# CC2756 register map
File version: 1.0
CPU: CM4 r0p4, little endian, no MPU, no FPU, VTOR, 3 interrupt priority bits
Registers are 32-bit, read-write, reset 0x0 unless marked. A register's access mark holds for its fields unless they carry their own. Offsets are from the block's base; [hi:lo] are bit positions; {n}, {i} and the like mark numbered series; 'fields as' and 'values as' point back to an identical list.

## LRFDPBE32
Base 0x40081400
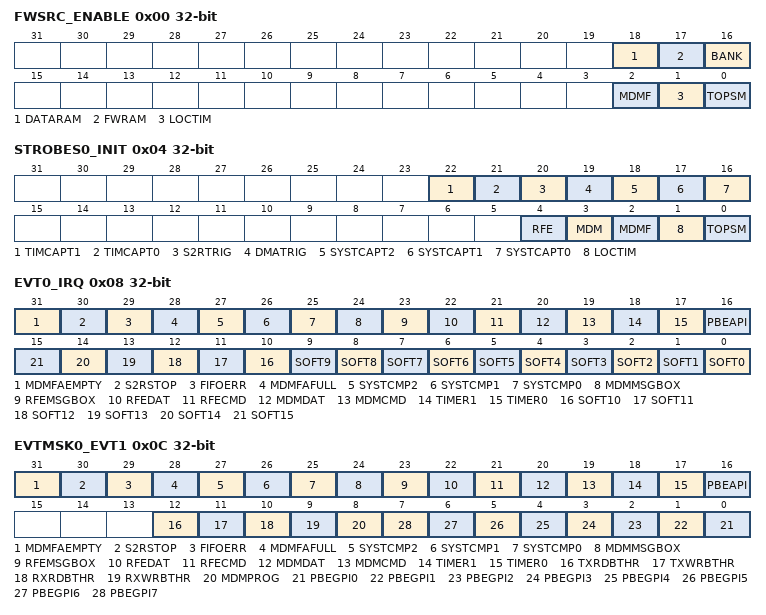
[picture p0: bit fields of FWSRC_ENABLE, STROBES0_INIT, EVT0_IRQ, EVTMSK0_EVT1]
0x00 FWSRC_ENABLE — Internal. Only to be used through TI provided API.
  [18] DATARAM — Internal. Only to be used through TI provided API.
    1=S2RRAM (Internal. Only to be used through TI provided API.); 0=PBERAM (Internal. Only to be used through TI provided API.)
  [17] FWRAM — Internal. Only to be used through TI provided API.
    values as DATARAM
  [16] BANK — Internal. Only to be used through TI provided API.
    1=ONE (Internal. Only to be used through TI provided API.); 0=ZERO (Internal. Only to be used through TI provided API.)
  [2] MDMF — Internal. Only to be used through TI provided API.
    1=EN (Internal. Only to be used through TI provided API.); 0=DIS (Internal. Only to be used through TI provided API.)
  [1] LOCTIM — Internal. Only to be used through TI provided API.
    values as MDMF
  [0] TOPSM — Internal. Only to be used through TI provided API.
    values as MDMF
0x04 STROBES0_INIT wo — Internal. Only to be used through TI provided API.
  [22] TIMCAPT1 — Internal. Only to be used through TI provided API.
    values as FWSRC_ENABLE.BANK
  [21] TIMCAPT0 — Internal. Only to be used through TI provided API.
    values as FWSRC_ENABLE.BANK
  [20] S2RTRIG — Internal. Only to be used through TI provided API.
    1=ARM (Internal. Only to be used through TI provided API.); 0=NO_EFFECT (Internal. Only to be used through TI provided API.)
  [19] DMATRIG — Internal. Only to be used through TI provided API.
    values as S2RTRIG
  [18] SYSTCAPT2 — Internal. Only to be used through TI provided API.
    values as FWSRC_ENABLE.BANK
  [17] SYSTCAPT1 — Internal. Only to be used through TI provided API.
    values as FWSRC_ENABLE.BANK
  [16] SYSTCAPT0 — Internal. Only to be used through TI provided API.
    values as FWSRC_ENABLE.BANK
  [4] RFE — Internal. Only to be used through TI provided API.
    1=RESET (Internal. Only to be used through TI provided API.); 0=NO_EFFECT (Internal. Only to be used through TI provided API.)
  [3] MDM — Internal. Only to be used through TI provided API.
    values as RFE
  [2] MDMF — Internal. Only to be used through TI provided API.
    values as RFE
  [1] LOCTIM — Internal. Only to be used through TI provided API.
    values as RFE
  [0] TOPSM — Internal. Only to be used through TI provided API.
    values as RFE
0x08 EVT0_IRQ wo — Internal. Only to be used through TI provided API.
  [31] MDMFAEMPTY ro — Internal. Only to be used through TI provided API.
    values as FWSRC_ENABLE.BANK
  [30] S2RSTOP ro — Internal. Only to be used through TI provided API.
    values as FWSRC_ENABLE.BANK
  [29] FIFOERR ro — Internal. Only to be used through TI provided API.
    values as FWSRC_ENABLE.BANK
  [28] MDMFAFULL ro — Internal. Only to be used through TI provided API.
    values as FWSRC_ENABLE.BANK
  [27] SYSTCMP2 ro — Internal. Only to be used through TI provided API.
    values as FWSRC_ENABLE.BANK
  [26] SYSTCMP1 ro — Internal. Only to be used through TI provided API.
    values as FWSRC_ENABLE.BANK
  [25] SYSTCMP0 ro — Internal. Only to be used through TI provided API.
    values as FWSRC_ENABLE.BANK
  [24] MDMMSGBOX ro — Internal. Only to be used through TI provided API.
    values as FWSRC_ENABLE.BANK
  [23] RFEMSGBOX ro — Internal. Only to be used through TI provided API.
    values as FWSRC_ENABLE.BANK
  [22] RFEDAT ro — Internal. Only to be used through TI provided API.
    values as FWSRC_ENABLE.BANK
  [21] RFECMD ro — Internal. Only to be used through TI provided API.
    values as FWSRC_ENABLE.BANK
  [20] MDMDAT ro — Internal. Only to be used through TI provided API.
    values as FWSRC_ENABLE.BANK
  [19] MDMCMD ro — Internal. Only to be used through TI provided API.
    values as FWSRC_ENABLE.BANK
  [18] TIMER1 ro — Internal. Only to be used through TI provided API.
    values as FWSRC_ENABLE.BANK
  [17] TIMER0 ro — Internal. Only to be used through TI provided API.
    values as FWSRC_ENABLE.BANK
  [16] PBEAPI ro — Internal. Only to be used through TI provided API.
    values as FWSRC_ENABLE.BANK
  [n] SOFT{n} (n=0..15) — Internal. Only to be used through TI provided API.
    1=ON (Internal. Only to be used through TI provided API.); 0=OFF (Internal. Only to be used through TI provided API.)
0x0C EVTMSK0_EVT1 ro — Internal. Only to be used through TI provided API.
  [31] MDMFAEMPTY — Internal. Only to be used through TI provided API.
    values as FWSRC_ENABLE.MDMF
  [30] S2RSTOP — Internal. Only to be used through TI provided API.
    values as FWSRC_ENABLE.MDMF
  [29] FIFOERR — Internal. Only to be used through TI provided API.
    values as FWSRC_ENABLE.MDMF
  [28] MDMFAFULL — Internal. Only to be used through TI provided API.
    values as FWSRC_ENABLE.MDMF
  [27] SYSTCMP2 — Internal. Only to be used through TI provided API.
    values as FWSRC_ENABLE.MDMF
  [26] SYSTCMP1 — Internal. Only to be used through TI provided API.
    values as FWSRC_ENABLE.MDMF
  [25] SYSTCMP0 — Internal. Only to be used through TI provided API.
    values as FWSRC_ENABLE.MDMF
  [24] MDMMSGBOX — Internal. Only to be used through TI provided API.
    values as FWSRC_ENABLE.MDMF
  [23] RFEMSGBOX — Internal. Only to be used through TI provided API.
    values as FWSRC_ENABLE.MDMF
  [22] RFEDAT — Internal. Only to be used through TI provided API.
    values as FWSRC_ENABLE.MDMF
  [21] RFECMD — Internal. Only to be used through TI provided API.
    values as FWSRC_ENABLE.MDMF
  [20] MDMDAT — Internal. Only to be used through TI provided API.
    values as FWSRC_ENABLE.MDMF
  [19] MDMCMD — Internal. Only to be used through TI provided API.
    values as FWSRC_ENABLE.MDMF
  [18] TIMER1 — Internal. Only to be used through TI provided API.
    values as FWSRC_ENABLE.MDMF
  [17] TIMER0 — Internal. Only to be used through TI provided API.
    values as FWSRC_ENABLE.MDMF
  [16] PBEAPI — Internal. Only to be used through TI provided API.
    values as FWSRC_ENABLE.MDMF
  [12] TXRDBTHR — Internal. Only to be used through TI provided API.
    1=MET (Internal. Only to be used through TI provided API.); 0=BELOW (Internal. Only to be used through TI provided API.)
  [11] TXWRBTHR — Internal. Only to be used through TI provided API.
    values as TXRDBTHR
  [10] RXRDBTHR — Internal. Only to be used through TI provided API.
    values as TXRDBTHR
  [9] RXWRBTHR — Internal. Only to be used through TI provided API.
    values as TXRDBTHR
  [8] MDMPROG — Internal. Only to be used through TI provided API.
    values as FWSRC_ENABLE.BANK
  [n] PBEGPI{n} (n=0..7) — Internal. Only to be used through TI provided API.
    values as FWSRC_ENABLE.BANK
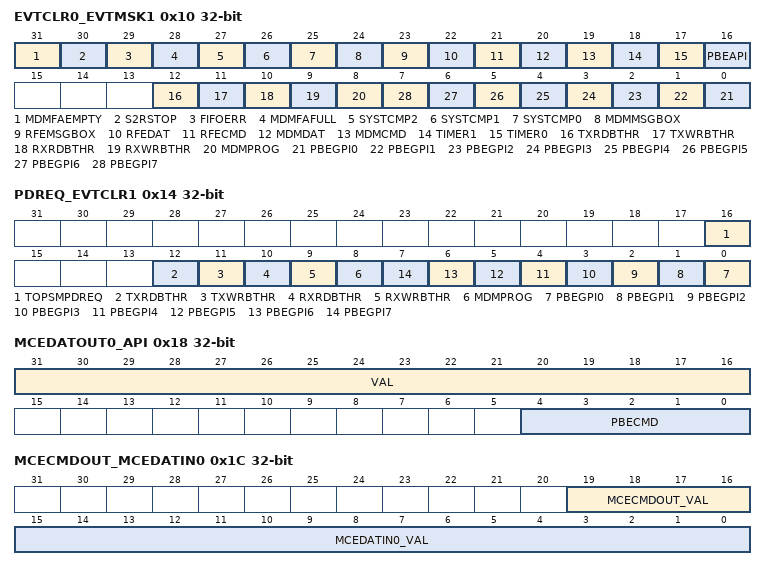
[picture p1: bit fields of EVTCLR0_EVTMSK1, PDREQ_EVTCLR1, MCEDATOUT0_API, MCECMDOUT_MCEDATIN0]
0x10 EVTCLR0_EVTMSK1 — Internal. Only to be used through TI provided API.
  [31] MDMFAEMPTY wo — Internal. Only to be used through TI provided API.
    1=CLEAR (Internal. Only to be used through TI provided API.); 0=RETAIN (Internal. Only to be used through TI provided API.)
  [30] S2RSTOP wo — Internal. Only to be used through TI provided API.
    values as MDMFAEMPTY
  [29] FIFOERR wo — Internal. Only to be used through TI provided API.
    values as MDMFAEMPTY
  [28] MDMFAFULL wo — Internal. Only to be used through TI provided API.
    values as MDMFAEMPTY
  [27] SYSTCMP2 wo — Internal. Only to be used through TI provided API.
    values as MDMFAEMPTY
  [26] SYSTCMP1 wo — Internal. Only to be used through TI provided API.
    values as MDMFAEMPTY
  [25] SYSTCMP0 wo — Internal. Only to be used through TI provided API.
    values as MDMFAEMPTY
  [24] MDMMSGBOX wo — Internal. Only to be used through TI provided API.
    values as MDMFAEMPTY
  [23] RFEMSGBOX wo — Internal. Only to be used through TI provided API.
    values as MDMFAEMPTY
  [22] RFEDAT wo — Internal. Only to be used through TI provided API.
    values as MDMFAEMPTY
  [21] RFECMD wo — Internal. Only to be used through TI provided API.
    values as MDMFAEMPTY
  [20] MDMDAT wo — Internal. Only to be used through TI provided API.
    values as MDMFAEMPTY
  [19] MDMCMD wo — Internal. Only to be used through TI provided API.
    values as MDMFAEMPTY
  [18] TIMER1 wo — Internal. Only to be used through TI provided API.
    values as MDMFAEMPTY
  [17] TIMER0 wo — Internal. Only to be used through TI provided API.
    values as MDMFAEMPTY
  [16] PBEAPI wo — Internal. Only to be used through TI provided API.
    values as MDMFAEMPTY
  [12] TXRDBTHR — Internal. Only to be used through TI provided API.
    values as FWSRC_ENABLE.MDMF
  [11] TXWRBTHR — Internal. Only to be used through TI provided API.
    values as FWSRC_ENABLE.MDMF
  [10] RXRDBTHR — Internal. Only to be used through TI provided API.
    values as FWSRC_ENABLE.MDMF
  [9] RXWRBTHR — Internal. Only to be used through TI provided API.
    values as FWSRC_ENABLE.MDMF
  [8] MDMPROG — Internal. Only to be used through TI provided API.
    values as FWSRC_ENABLE.MDMF
  [n] PBEGPI{n} (n=0..7) — Internal. Only to be used through TI provided API.
    values as FWSRC_ENABLE.MDMF
0x14 PDREQ_EVTCLR1 wo — Internal. Only to be used through TI provided API.
  [16] TOPSMPDREQ — Internal. Only to be used through TI provided API.
    values as EVT0_IRQ.SOFT0
  [12] TXRDBTHR — Internal. Only to be used through TI provided API.
    values as EVTCLR0_EVTMSK1.MDMFAEMPTY
  [11] TXWRBTHR — Internal. Only to be used through TI provided API.
    values as EVTCLR0_EVTMSK1.MDMFAEMPTY
  [10] RXRDBTHR — Internal. Only to be used through TI provided API.
    values as EVTCLR0_EVTMSK1.MDMFAEMPTY
  [9] RXWRBTHR — Internal. Only to be used through TI provided API.
    values as EVTCLR0_EVTMSK1.MDMFAEMPTY
  [8] MDMPROG — Internal. Only to be used through TI provided API.
    values as EVTCLR0_EVTMSK1.MDMFAEMPTY
  [n] PBEGPI{n} (n=0..7) — Internal. Only to be used through TI provided API.
    values as EVTCLR0_EVTMSK1.MDMFAEMPTY
0x18 MCEDATOUT0_API — Internal. Only to be used through TI provided API.
  [31:16] VAL — Internal. Only to be used through TI provided API.
    0xFFFF=ALLONES (Internal. Only to be used through TI provided API.); 0=ALLZEROS (Internal. Only to be used through TI provided API.)
  [4:0] PBECMD — Internal. Only to be used through TI provided API.
    31=ALLONES (Internal. Only to be used through TI provided API.); 0=ALLZEROS (Internal. Only to be used through TI provided API.)
0x1C MCECMDOUT_MCEDATIN0 ro — Internal. Only to be used through TI provided API.
  [19:16] MCECMDOUT_VAL — Internal. Only to be used through TI provided API.
    15=ALLONES (Internal. Only to be used through TI provided API.); 0=ALLZEROS (Internal. Only to be used through TI provided API.)
  [15:0] MCEDATIN0_VAL — Internal. Only to be used through TI provided API.
    values as MCEDATOUT0_API.VAL
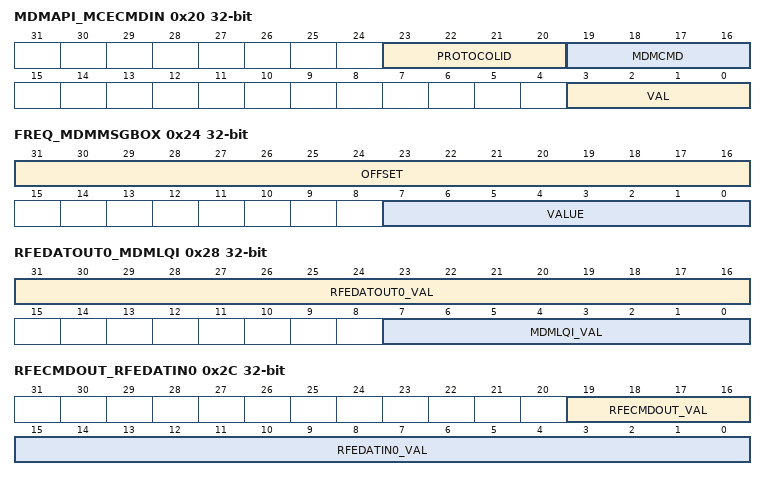
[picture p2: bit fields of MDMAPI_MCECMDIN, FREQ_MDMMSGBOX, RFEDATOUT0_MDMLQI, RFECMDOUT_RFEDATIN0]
0x20 MDMAPI_MCECMDIN ro — Internal. Only to be used through TI provided API.
  [all] fields
    values as MCECMDOUT_MCEDATIN0.MCECMDOUT_VAL
  [23:20] PROTOCOLID — Internal. Only to be used through TI provided API.
  [19:16] MDMCMD — Internal. Only to be used through TI provided API.
  [3:0] VAL — Internal. Only to be used through TI provided API.
0x24 FREQ_MDMMSGBOX ro — Internal. Only to be used through TI provided API.
  [31:16] OFFSET — Internal. Only to be used through TI provided API.
    values as MCEDATOUT0_API.VAL
  [7:0] VALUE — Internal. Only to be used through TI provided API.
    255=ALLONES (Internal. Only to be used through TI provided API.); 0=ALLZEROS (Internal. Only to be used through TI provided API.)
0x28 RFEDATOUT0_MDMLQI ro — Internal. Only to be used through TI provided API.
  [31:16] RFEDATOUT0_VAL — Internal. Only to be used through TI provided API.
    values as MCEDATOUT0_API.VAL
  [7:0] MDMLQI_VAL — Internal. Only to be used through TI provided API.
    values as FREQ_MDMMSGBOX.VALUE
0x2C RFECMDOUT_RFEDATIN0 ro — Internal. Only to be used through TI provided API.
  [19:16] RFECMDOUT_VAL — Internal. Only to be used through TI provided API.
    values as MCECMDOUT_MCEDATIN0.MCECMDOUT_VAL
  [15:0] RFEDATIN0_VAL — Internal. Only to be used through TI provided API.
    values as MCEDATOUT0_API.VAL
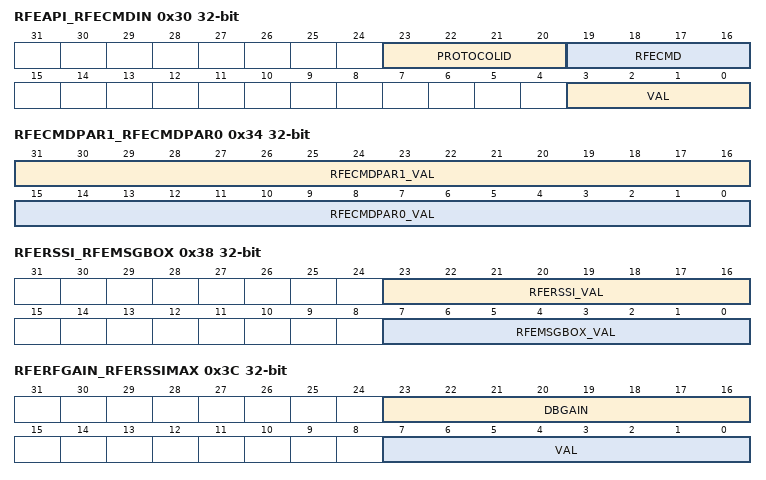
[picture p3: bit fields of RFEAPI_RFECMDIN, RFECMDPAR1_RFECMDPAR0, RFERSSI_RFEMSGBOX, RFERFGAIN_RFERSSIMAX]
0x30 RFEAPI_RFECMDIN ro — Internal. Only to be used through TI provided API.
  [all] fields
    values as MCECMDOUT_MCEDATIN0.MCECMDOUT_VAL
  [23:20] PROTOCOLID — Internal. Only to be used through TI provided API.
  [19:16] RFECMD — Internal. Only to be used through TI provided API.
  [3:0] VAL — Internal. Only to be used through TI provided API.
0x34 RFECMDPAR1_RFECMDPAR0 — Internal. Only to be used through TI provided API.
  [31:16] RFECMDPAR1_VAL — Internal. Only to be used through TI provided API.
    values as MCEDATOUT0_API.VAL
  [15:0] RFECMDPAR0_VAL — Internal. Only to be used through TI provided API.
    values as MCEDATOUT0_API.VAL
0x38 RFERSSI_RFEMSGBOX ro — Internal. Only to be used through TI provided API.
  [23:16] RFERSSI_VAL — Internal. Only to be used through TI provided API.
    values as FREQ_MDMMSGBOX.VALUE
  [7:0] RFEMSGBOX_VAL — Internal. Only to be used through TI provided API.
    values as FREQ_MDMMSGBOX.VALUE
0x3C RFERFGAIN_RFERSSIMAX ro — Internal. Only to be used through TI provided API.
  [23:16] DBGAIN — Internal. Only to be used through TI provided API.
    values as FREQ_MDMMSGBOX.VALUE
  [7:0] VAL — Internal. Only to be used through TI provided API.
    values as FREQ_MDMMSGBOX.VALUE
0x40 MDMSYNCA — Internal. Only to be used through TI provided API.
  [31:0] SWA
    values as MCEDATOUT0_API.VAL
0x44 MDMSYNCB — Internal. Only to be used through TI provided API.
  [31:0] SWB
    values as MCEDATOUT0_API.VAL
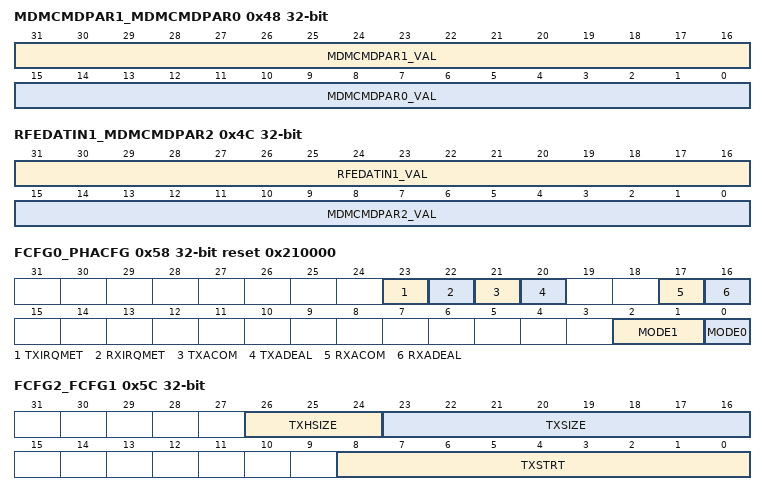
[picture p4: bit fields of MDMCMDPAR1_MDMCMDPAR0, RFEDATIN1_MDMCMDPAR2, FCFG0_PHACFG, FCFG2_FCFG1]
0x48 MDMCMDPAR1_MDMCMDPAR0 — Internal. Only to be used through TI provided API.
  [31:16] MDMCMDPAR1_VAL — Internal. Only to be used through TI provided API.
    values as MCEDATOUT0_API.VAL
  [15:0] MDMCMDPAR0_VAL — Internal. Only to be used through TI provided API.
    values as MCEDATOUT0_API.VAL
0x4C RFEDATIN1_MDMCMDPAR2 — Internal. Only to be used through TI provided API.
  [31:16] RFEDATIN1_VAL ro — Internal. Only to be used through TI provided API.
    values as MCEDATOUT0_API.VAL
  [15:0] MDMCMDPAR2_VAL — Internal. Only to be used through TI provided API.
    values as MCEDATOUT0_API.VAL
0x50 POLY0 — Internal. Only to be used through TI provided API.
  [31:0] VAL
    values as MCEDATOUT0_API.VAL
0x54 POLY1 — Internal. Only to be used through TI provided API.
  fields as POLY0
0x58 FCFG0_PHACFG reset 0x210000 — Internal. Only to be used through TI provided API.
  [23] TXIRQMET — Internal. Only to be used through TI provided API.
    1=TXRDBTHR (Internal. Only to be used through TI provided API.); 0=TXWRBTHR (Internal. Only to be used through TI provided API.)
  [22] RXIRQMET — Internal. Only to be used through TI provided API.
    1=RXWRBTHR (Internal. Only to be used through TI provided API.); 0=RXRDBTHR (Internal. Only to be used through TI provided API.)
  [21] TXACOM — Internal. Only to be used through TI provided API.
    values as FWSRC_ENABLE.MDMF
  [20] TXADEAL — Internal. Only to be used through TI provided API.
    values as FWSRC_ENABLE.MDMF
  [17] RXACOM — Internal. Only to be used through TI provided API.
    values as FWSRC_ENABLE.MDMF
  [16] RXADEAL — Internal. Only to be used through TI provided API.
    values as FWSRC_ENABLE.MDMF
  [2:1] MODE1 — Internal. Only to be used through TI provided API.
    2=PARAL (Internal. Only to be used through TI provided API.); 1=CASC (Internal. Only to be used through TI provided API.); 0=INDEP (Internal. Only to be used through TI provided API.)
  [0] MODE0 — Internal. Only to be used through TI provided API.
    1=WHITE (Internal. Only to be used through TI provided API.); 0=CRC (Internal. Only to be used through TI provided API.)
0x5C FCFG2_FCFG1 — Internal. Only to be used through TI provided API.
  [26:24] TXHSIZE — Internal. Only to be used through TI provided API.
    2=WORD (Internal. Only to be used through TI provided API.); 1=HALFW (Internal. Only to be used through TI provided API.); 0=BYTE (Internal. Only to be used through TI provided API.)
  [23:16] TXSIZE — Internal. Only to be used through TI provided API.
    255=ONES (Internal. Only to be used through TI provided API.); 0=ZEROS (Internal. Only to be used through TI provided API.)
  [8:0] TXSTRT — Internal. Only to be used through TI provided API.
    0x1FF=ONES (Internal. Only to be used through TI provided API.); 0=ZEROS (Internal. Only to be used through TI provided API.)
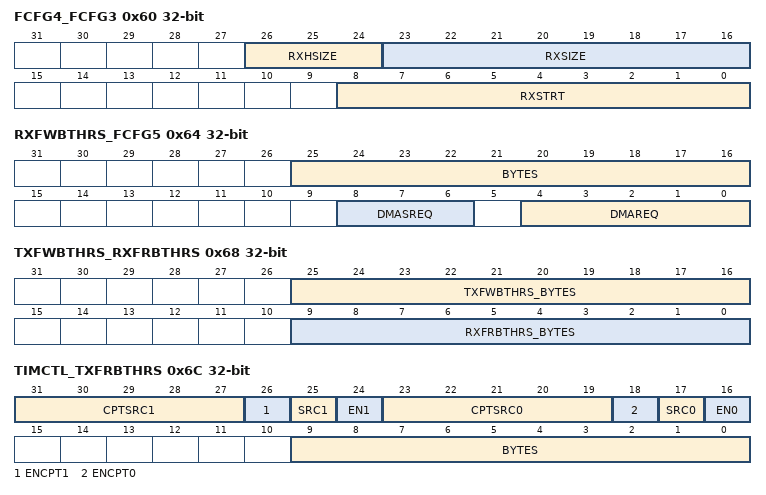
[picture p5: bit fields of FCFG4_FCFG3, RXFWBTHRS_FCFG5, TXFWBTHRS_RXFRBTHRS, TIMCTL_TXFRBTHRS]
0x60 FCFG4_FCFG3 — Internal. Only to be used through TI provided API.
  [26:24] RXHSIZE — Internal. Only to be used through TI provided API.
    values as FCFG2_FCFG1.TXHSIZE
  [23:16] RXSIZE — Internal. Only to be used through TI provided API.
    values as FCFG2_FCFG1.TXSIZE
  [8:0] RXSTRT — Internal. Only to be used through TI provided API.
    values as FCFG2_FCFG1.TXSTRT
0x64 RXFWBTHRS_FCFG5 — Internal. Only to be used through TI provided API.
  [25:16] BYTES — Internal. Only to be used through TI provided API.
    0x3FF=ALLONES (Internal. Only to be used through TI provided API.); 0=ALLZEROS (Internal. Only to be used through TI provided API.)
  [8:6] DMASREQ — Internal. Only to be used through TI provided API.
    4=TXFIFOFREE (Internal. Only to be used through TI provided API.); 3=TXFIFOMD (Internal. Only to be used through TI provided API.); 2=RXFIFOFREE (Internal. Only to be used through TI provided API.); 1=RXFIFOMD (Internal. Only to be used through TI provided API.); 0=NONE (Internal. Only to be used through TI provided API.)
  [4:0] DMAREQ — Internal. Only to be used through TI provided API.
    15=TXFIFO_COMMIT (Internal. Only to be used through TI provided API.); 14=TXFIFO_DISCARD (Internal. Only to be used through TI provided API.); 13=TXFIFO_RETRY (Internal. Only to be used through TI provided API.); 12=TXFIFO_DEALLOC (Internal. Only to be used through TI provided API.); 11=TXFIFO_RESET (Internal. Only to be used through TI provided API.); 10=TXWRBTHR_MET (Internal. Only to be used through TI provided API.); 9=TXRDBTHR_MET (Internal. Only to be used through TI provided API.); 7=RXFIFO_COMMIT (Internal. Only to be used through TI provided API.); 6=RXFIFO_DISCARD (Internal. Only to be used through TI provided API.); 5=RXFIFO_RETRY (Internal. Only to be used through TI provided API.); 4=RXFIFO_DEALLOC (Internal. Only to be used through TI provided API.); 3=RXFIFO_RESET (Internal. Only to be used through TI provided API.); 2=RXWRBTHR_MET (Internal. Only to be used through TI provided API.); 1=RXRDBTHR_MET (Internal. Only to be used through TI provided API.); 0=NONE (Internal. Only to be used through TI provided API.)
0x68 TXFWBTHRS_RXFRBTHRS — Internal. Only to be used through TI provided API.
  [25:16] TXFWBTHRS_BYTES — Internal. Only to be used through TI provided API.
    values as RXFWBTHRS_FCFG5.BYTES
  [9:0] RXFRBTHRS_BYTES — Internal. Only to be used through TI provided API.
    values as RXFWBTHRS_FCFG5.BYTES
0x6C TIMCTL_TXFRBTHRS — Internal. Only to be used through TI provided API.
  [31:27] CPTSRC1 — Internal. Only to be used through TI provided API.
    values as MCEDATOUT0_API.PBECMD
  [26] ENCPT1 — Internal. Only to be used through TI provided API.
    values as EVT0_IRQ.SOFT0
  [25] SRC1 — Internal. Only to be used through TI provided API.
    1=PRE1 (Internal. Only to be used through TI provided API.); 0=CLK (Internal. Only to be used through TI provided API.)
  [24] EN1 — Internal. Only to be used through TI provided API.
    values as EVT0_IRQ.SOFT0
  [23:19] CPTSRC0 — Internal. Only to be used through TI provided API.
    values as MCEDATOUT0_API.PBECMD
  [18] ENCPT0 — Internal. Only to be used through TI provided API.
    values as EVT0_IRQ.SOFT0
  [17] SRC0 — Internal. Only to be used through TI provided API.
    1=PRE0 (Internal. Only to be used through TI provided API.); 0=CLK (Internal. Only to be used through TI provided API.)
  [16] EN0 — Internal. Only to be used through TI provided API.
    values as EVT0_IRQ.SOFT0
  [9:0] BYTES — Internal. Only to be used through TI provided API.
    values as RXFWBTHRS_FCFG5.BYTES
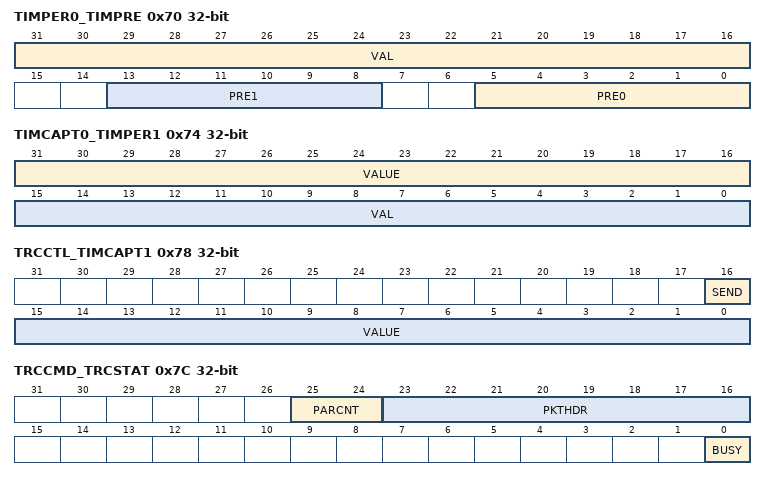
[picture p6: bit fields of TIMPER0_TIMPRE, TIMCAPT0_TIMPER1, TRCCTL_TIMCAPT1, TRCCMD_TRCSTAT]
0x70 TIMPER0_TIMPRE — Internal. Only to be used through TI provided API.
  [31:16] VAL — Internal. Only to be used through TI provided API.
    values as MCEDATOUT0_API.VAL
  [13:8] PRE1 — Internal. Only to be used through TI provided API.
    63=DIV64 (Internal. Only to be used through TI provided API.); 0=NO_DIV (Internal. Only to be used through TI provided API.)
  [5:0] PRE0 — Internal. Only to be used through TI provided API.
    values as PRE1
0x74 TIMCAPT0_TIMPER1 — Internal. Only to be used through TI provided API.
  [31:16] VALUE ro — Internal. Only to be used through TI provided API.
    values as MCEDATOUT0_API.VAL
  [15:0] VAL — Internal. Only to be used through TI provided API.
    values as MCEDATOUT0_API.VAL
0x78 TRCCTL_TIMCAPT1 ro — Internal. Only to be used through TI provided API.
  [16] SEND wo — Internal. Only to be used through TI provided API.
    values as FWSRC_ENABLE.BANK
  [15:0] VALUE — Internal. Only to be used through TI provided API.
    values as MCEDATOUT0_API.VAL
0x7C TRCCMD_TRCSTAT ro — Internal. Only to be used through TI provided API.
  [25:24] PARCNT — Internal. Only to be used through TI provided API.
    3=ALLONES (Internal. Only to be used through TI provided API.); 0=ALLZEROS (Internal. Only to be used through TI provided API.)
  [23:16] PKTHDR — Internal. Only to be used through TI provided API.
    values as FREQ_MDMMSGBOX.VALUE
  [0] BUSY — Internal. Only to be used through TI provided API.
    values as FWSRC_ENABLE.BANK
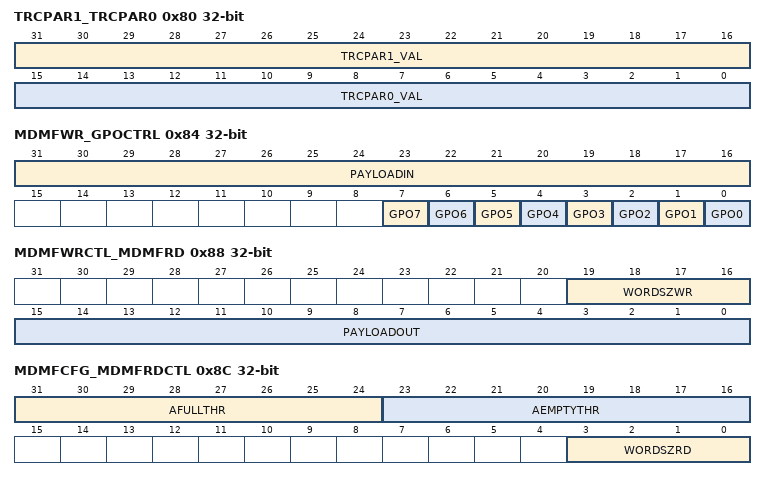
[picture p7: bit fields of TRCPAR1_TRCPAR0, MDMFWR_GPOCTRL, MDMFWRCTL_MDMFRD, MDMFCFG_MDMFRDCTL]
0x80 TRCPAR1_TRCPAR0 — Internal. Only to be used through TI provided API.
  [31:16] TRCPAR1_VAL — Internal. Only to be used through TI provided API.
    values as MCEDATOUT0_API.VAL
  [15:0] TRCPAR0_VAL — Internal. Only to be used through TI provided API.
    values as MCEDATOUT0_API.VAL
0x84 MDMFWR_GPOCTRL — Internal. Only to be used through TI provided API.
  [31:16] PAYLOADIN — Internal. Only to be used through TI provided API.
    values as MCEDATOUT0_API.VAL
  [n] GPO{n} (n=0..7) — Internal. Only to be used through TI provided API.
    values as FWSRC_ENABLE.BANK
0x88 MDMFWRCTL_MDMFRD ro — Internal. Only to be used through TI provided API.
  [19:16] WORDSZWR — Internal. Only to be used through TI provided API.
    {v}=BITS{v+1} (Internal. Only to be used through TI provided API.) (v=0..15)
  [15:0] PAYLOADOUT — Internal. Only to be used through TI provided API.
    values as MCEDATOUT0_API.VAL
0x8C MDMFCFG_MDMFRDCTL — Internal. Only to be used through TI provided API.
  [31:24] AFULLTHR — Internal. Only to be used through TI provided API.
    values as FREQ_MDMMSGBOX.VALUE
  [23:16] AEMPTYTHR — Internal. Only to be used through TI provided API.
    values as FREQ_MDMMSGBOX.VALUE
  [3:0] WORDSZRD — Internal. Only to be used through TI provided API.
    values as MDMFWRCTL_MDMFRD.WORDSZWR
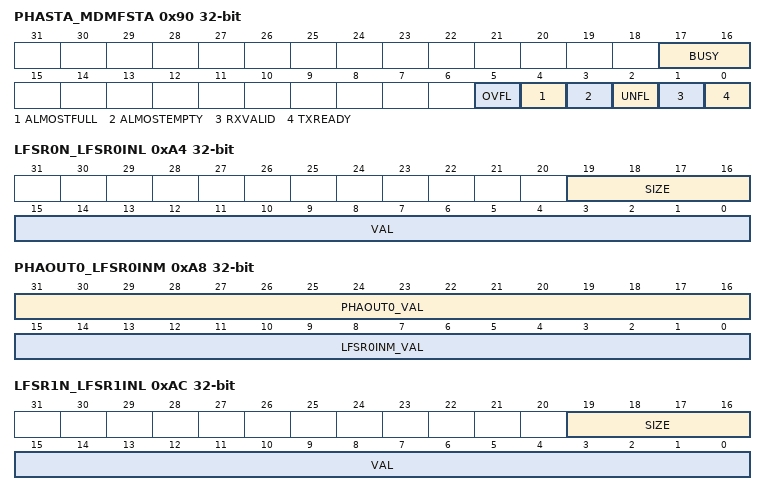
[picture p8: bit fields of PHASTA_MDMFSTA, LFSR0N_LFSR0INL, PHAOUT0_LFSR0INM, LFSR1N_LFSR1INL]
0x90 PHASTA_MDMFSTA ro — Internal. Only to be used through TI provided API.
  [17:16] BUSY — Internal. Only to be used through TI provided API.
    1=BUSY (Internal. Only to be used through TI provided API.); 0=IDLE (Internal. Only to be used through TI provided API.)
  [5] OVFL — Internal. Only to be used through TI provided API.
    values as FWSRC_ENABLE.BANK
  [4] ALMOSTFULL — Internal. Only to be used through TI provided API.
    values as FWSRC_ENABLE.BANK
  [3] ALMOSTEMPTY — Internal. Only to be used through TI provided API.
    values as FWSRC_ENABLE.BANK
  [2] UNFL — Internal. Only to be used through TI provided API.
    values as FWSRC_ENABLE.BANK
  [1] RXVALID — Internal. Only to be used through TI provided API.
    values as FWSRC_ENABLE.BANK
  [0] TXREADY — Internal. Only to be used through TI provided API.
    values as FWSRC_ENABLE.BANK
0x94 LFSR0 reset 0xFFFFFFFF — Internal. Only to be used through TI provided API.
  fields as POLY0
0x98 LFSR0BR reset 0xFFFFFFFF — Internal. Only to be used through TI provided API.
  fields as POLY0
0x9C LFSR1 reset 0xFFFFFFFF — Internal. Only to be used through TI provided API.
  fields as POLY0
0xA0 LFSR1BR reset 0xFFFFFFFF — Internal. Only to be used through TI provided API.
  fields as POLY0
0xA4 LFSR0N_LFSR0INL wo — Internal. Only to be used through TI provided API.
  [19:16] SIZE — Internal. Only to be used through TI provided API.
    values as MCECMDOUT_MCEDATIN0.MCECMDOUT_VAL
  [15:0] VAL — Internal. Only to be used through TI provided API.
    values as TRCCMD_TRCSTAT.PARCNT
0xA8 PHAOUT0_LFSR0INM wo — Internal. Only to be used through TI provided API.
  [31:16] PHAOUT0_VAL — Internal. Only to be used through TI provided API.
    0xDCD7=ALLONES (Internal. Only to be used through TI provided API.); 0=ALLZEROS (Internal. Only to be used through TI provided API.)
  [15:0] LFSR0INM_VAL — Internal. Only to be used through TI provided API.
    values as FWSRC_ENABLE.BANK
0xAC LFSR1N_LFSR1INL wo — Internal. Only to be used through TI provided API.
  fields as LFSR0N_LFSR0INL
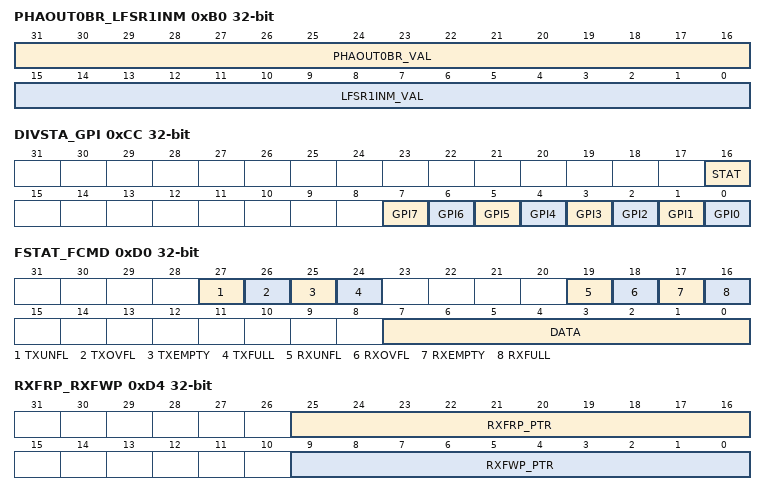
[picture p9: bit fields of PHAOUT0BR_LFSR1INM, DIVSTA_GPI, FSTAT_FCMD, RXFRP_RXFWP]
0xB0 PHAOUT0BR_LFSR1INM wo — Internal. Only to be used through TI provided API.
  [31:16] PHAOUT0BR_VAL ro — Internal. Only to be used through TI provided API.
    values as MCEDATOUT0_API.VAL
  [15:0] LFSR1INM_VAL — Internal. Only to be used through TI provided API.
    values as FWSRC_ENABLE.BANK
0xB4 DIVIDEND wo — Internal. Only to be used through TI provided API.
  fields as POLY0
0xB8 DIVISOR — Internal. Only to be used through TI provided API.
  fields as POLY0
0xBC QUOTIENT ro — Internal. Only to be used through TI provided API.
  fields as POLY0
{0xC0+4i} SYSTIM{i} ro (i=0..2) — Internal. Only to be used through TI provided API.
  [31:0] VAL
    values as FWSRC_ENABLE.BANK
0xCC DIVSTA_GPI ro — Internal. Only to be used through TI provided API.
  [16] STAT — Internal. Only to be used through TI provided API.
    values as PHASTA_MDMFSTA.BUSY
  [n] GPI{n} (n=0..7) — Internal. Only to be used through TI provided API.
    values as FWSRC_ENABLE.BANK
0xD0 FSTAT_FCMD wo — Internal. Only to be used through TI provided API.
  [27] TXUNFL ro — Internal. Only to be used through TI provided API.
    1=TRUE (Internal. Only to be used through TI provided API.); 0=FALSE (Internal. Only to be used through TI provided API.)
  [26] TXOVFL ro — Internal. Only to be used through TI provided API.
    values as TXUNFL
  [25] TXEMPTY ro — Internal. Only to be used through TI provided API.
    values as TXUNFL
  [24] TXFULL ro — Internal. Only to be used through TI provided API.
    values as TXUNFL
  [19] RXUNFL ro — Internal. Only to be used through TI provided API.
    values as TXUNFL
  [18] RXOVFL ro — Internal. Only to be used through TI provided API.
    values as TXUNFL
  [17] RXEMPTY ro — Internal. Only to be used through TI provided API.
    values as TXUNFL
  [16] RXFULL ro — Internal. Only to be used through TI provided API.
    values as TXUNFL
  [7:0] DATA — Internal. Only to be used through TI provided API.
    15=FIFO_COMMIT (Internal. Only to be used through TI provided API.); 14=FIFO_DISCARD (Internal. Only to be used through TI provided API.); 13=FIFO_RETRY (Internal. Only to be used through TI provided API.); 12=FIFO_DEALLOC (Internal. Only to be used through TI provided API.); 11=FIFO_RESET (Internal. Only to be used through TI provided API.); 10=RXFIFO_RETRY (Internal. Only to be used through TI provided API.); 9=RXFIFO_DISCARD (Internal. Only to be used through TI provided API.); 8=RXFIFO_COMMIT (Internal. Only to be used through TI provided API.); 7=TXFIFO_RESET (Internal. Only to be used through TI provided API.); 6=TXFIFO_DEALLOC (Internal. Only to be used through TI provided API.); 5=TXFIFO_RETRY (Internal. Only to be used through TI provided API.); 4=TXFIFO_DISCARD (Internal. Only to be used through TI provided API.); 3=TXFIFO_COMMIT (Internal. Only to be used through TI provided API.); 2=RXFIFO_DEALLOC (Internal. Only to be used through TI provided API.); 1=RXFIFO_RESET (Internal. Only to be used through TI provided API.)
0xD4 RXFRP_RXFWP — Internal. Only to be used through TI provided API.
  [25:16] RXFRP_PTR — Internal. Only to be used through TI provided API.
    values as RXFWBTHRS_FCFG5.BYTES
  [9:0] RXFWP_PTR — Internal. Only to be used through TI provided API.
    values as RXFWBTHRS_FCFG5.BYTES
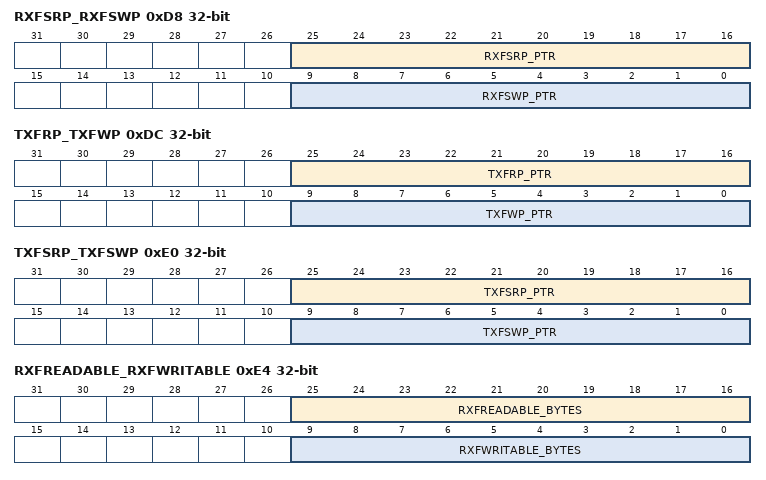
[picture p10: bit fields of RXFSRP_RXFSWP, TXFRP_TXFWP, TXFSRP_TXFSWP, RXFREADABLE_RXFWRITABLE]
0xD8 RXFSRP_RXFSWP — Internal. Only to be used through TI provided API.
  [25:16] RXFSRP_PTR — Internal. Only to be used through TI provided API.
    values as RXFWBTHRS_FCFG5.BYTES
  [9:0] RXFSWP_PTR — Internal. Only to be used through TI provided API.
    values as RXFWBTHRS_FCFG5.BYTES
0xDC TXFRP_TXFWP — Internal. Only to be used through TI provided API.
  [25:16] TXFRP_PTR — Internal. Only to be used through TI provided API.
    values as RXFWBTHRS_FCFG5.BYTES
  [9:0] TXFWP_PTR — Internal. Only to be used through TI provided API.
    values as RXFWBTHRS_FCFG5.BYTES
0xE0 TXFSRP_TXFSWP — Internal. Only to be used through TI provided API.
  [25:16] TXFSRP_PTR — Internal. Only to be used through TI provided API.
    0x3FF=ALLONES_2 (Internal. Only to be used through TI provided API.); 0=ALLZEROS (Internal. Only to be used through TI provided API.)
  [9:0] TXFSWP_PTR — Internal. Only to be used through TI provided API.
    values as RXFWBTHRS_FCFG5.BYTES
0xE4 RXFREADABLE_RXFWRITABLE ro — Internal. Only to be used through TI provided API.
  [25:16] RXFREADABLE_BYTES — Internal. Only to be used through TI provided API.
    values as RXFWBTHRS_FCFG5.BYTES
  [9:0] RXFWRITABLE_BYTES — Internal. Only to be used through TI provided API.
    values as RXFWBTHRS_FCFG5.BYTES
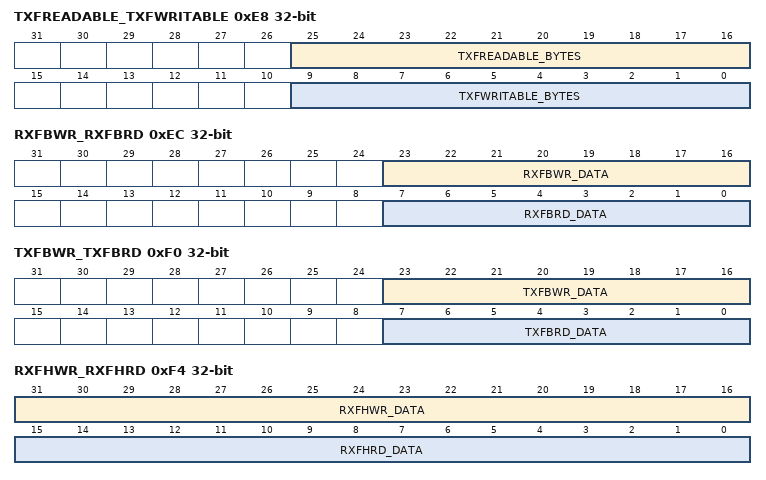
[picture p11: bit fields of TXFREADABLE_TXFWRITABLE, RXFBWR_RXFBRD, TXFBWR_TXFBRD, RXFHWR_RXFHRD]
0xE8 TXFREADABLE_TXFWRITABLE ro — Internal. Only to be used through TI provided API.
  [25:16] TXFREADABLE_BYTES — Internal. Only to be used through TI provided API.
    values as RXFWBTHRS_FCFG5.BYTES
  [9:0] TXFWRITABLE_BYTES — Internal. Only to be used through TI provided API.
    values as RXFWBTHRS_FCFG5.BYTES
0xEC RXFBWR_RXFBRD ro — Internal. Only to be used through TI provided API.
  [23:16] RXFBWR_DATA wo — Internal. Only to be used through TI provided API.
    values as FREQ_MDMMSGBOX.VALUE
  [7:0] RXFBRD_DATA — Internal. Only to be used through TI provided API.
    values as FREQ_MDMMSGBOX.VALUE
0xF0 TXFBWR_TXFBRD ro — Internal. Only to be used through TI provided API.
  [23:16] TXFBWR_DATA wo — Internal. Only to be used through TI provided API.
    values as FREQ_MDMMSGBOX.VALUE
  [7:0] TXFBRD_DATA — Internal. Only to be used through TI provided API.
    values as FREQ_MDMMSGBOX.VALUE
0xF4 RXFHWR_RXFHRD ro — Internal. Only to be used through TI provided API.
  [31:16] RXFHWR_DATA wo — Internal. Only to be used through TI provided API.
    values as MCEDATOUT0_API.VAL
  [15:0] RXFHRD_DATA — Internal. Only to be used through TI provided API.
    values as MCEDATOUT0_API.VAL
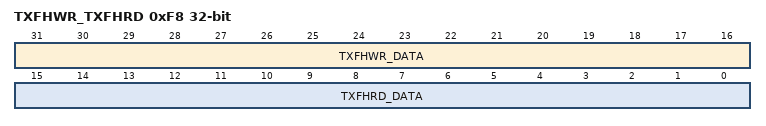
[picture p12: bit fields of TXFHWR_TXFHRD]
0xF8 TXFHWR_TXFHRD ro — Internal. Only to be used through TI provided API.
  [31:16] TXFHWR_DATA wo — Internal. Only to be used through TI provided API.
    values as MCEDATOUT0_API.VAL
  [15:0] TXFHRD_DATA — Internal. Only to be used through TI provided API.
    values as MCEDATOUT0_API.VAL
0xFC MCEDATIN1 ro — Internal. Only to be used through TI provided API.
  [15:0] VAL
    values as MCEDATOUT0_API.VAL
